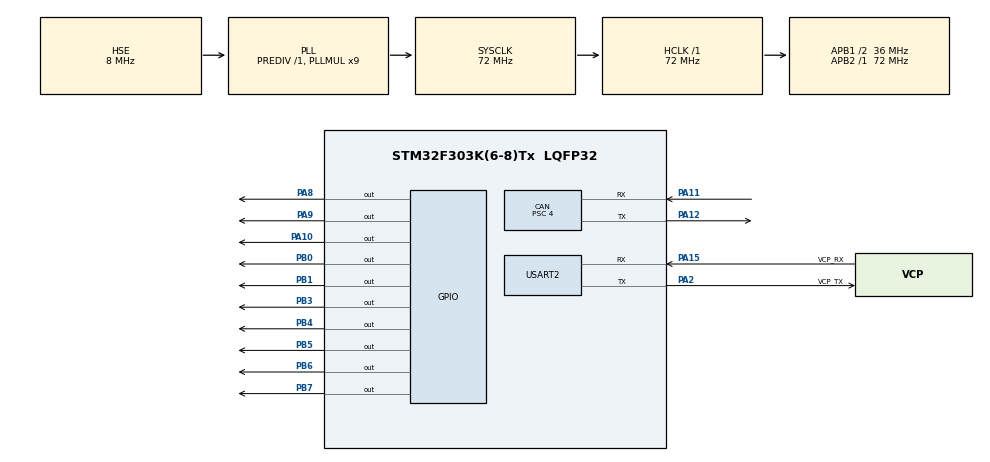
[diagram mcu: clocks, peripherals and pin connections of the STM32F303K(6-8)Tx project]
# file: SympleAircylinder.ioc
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CAN.ABOM=ENABLE
CAN.BS1=CAN_BS1_7TQ
CAN.CalculateTimeQuantum=111.11111111111111
CAN.Prescaler=4
CAN.SJW=CAN_SJW_2TQ
CAN.TXFP=ENABLE
Mcu.Family=STM32F3
Mcu.Name=STM32F303K(6-8)Tx
Mcu.Package=LQFP32
NVIC.CAN_RX0_IRQn=true\:0\:0\:false\:false\:true\:true\:true
NVIC.CAN_RX1_IRQn=true\:0\:0\:false\:false\:true\:true\:true
NVIC.PriorityGroup=NVIC_PRIORITYGROUP_4
PA10.GPIO_PuPd=GPIO_PULLDOWN
PA10.Signal=GPIO_Output
PA11.Mode=Master
PA11.Signal=CAN_RX
PA12.Mode=Master
PA12.Signal=CAN_TX
PA13.GPIO_Label=SWDIO
PA13.Mode=Serial_Wire
PA13.Signal=SYS_JTMS-SWDIO
PA14.GPIO_Label=SWCLK
PA14.Mode=Serial_Wire
PA14.Signal=SYS_JTCK-SWCLK
PA15.GPIO_Label=VCP_RX
PA15.Mode=Asynchronous
PA15.Signal=USART2_RX
PA2.GPIO_Label=VCP_TX
PA2.Mode=Asynchronous
PA2.Signal=USART2_TX
PA8.GPIO_PuPd=GPIO_PULLDOWN
PA8.Signal=GPIO_Output
PA9.GPIO_PuPd=GPIO_PULLDOWN
PA9.Signal=GPIO_Output
PB0.GPIO_PuPd=GPIO_NOPULL
PB0.Signal=GPIO_Output
PB1.GPIO_PuPd=GPIO_NOPULL
PB1.Signal=GPIO_Output
PB3.GPIO_PuPd=GPIO_PULLDOWN
PB3.Signal=GPIO_Output
PB4.GPIO_PuPd=GPIO_PULLDOWN
PB4.Signal=GPIO_Output
PB5.GPIO_PuPd=GPIO_PULLDOWN
PB5.Signal=GPIO_Output
PB6.GPIO_PuPd=GPIO_PULLDOWN
PB6.Signal=GPIO_Output
PB7.GPIO_PuPd=GPIO_PULLDOWN
PB7.Signal=GPIO_Output
PF0\ /\ OSC_IN.Mode=HSE-External-Oscillator
PF0\ /\ OSC_IN.Signal=RCC_OSC_IN
PF1\ /\ OSC_OUT.Mode=HSE-External-Oscillator
PF1\ /\ OSC_OUT.Signal=RCC_OSC_OUT
ProjectManager.HeapSize=0x200
ProjectManager.StackSize=0x400
ProjectManager.TargetToolchain=TrueSTUDIO
RCC.AHBFreq_Value=72000000
RCC.APB1CLKDivider=RCC_HCLK_DIV2
RCC.APB1Freq_Value=36000000
RCC.APB1TimFreq_Value=72000000
RCC.APB2Freq_Value=72000000
RCC.APB2TimFreq_Value=72000000
RCC.CortexFreq_Value=72000000
RCC.HCLKFreq_Value=72000000
RCC.HSE_VALUE=8000000
RCC.HSI_VALUE=8000000
RCC.PLLMUL=RCC_PLL_MUL9
RCC.PLLSourceVirtual=RCC_PLLSOURCE_HSE
RCC.SYSCLKFreq_VALUE=72000000
RCC.SYSCLKSourceVirtual=RCC_SYSCLKSOURCE_PLLCLK
USART2.VirtualMode-Asynchronous=VM_ASYNC
board=NUCLEO-F303K8

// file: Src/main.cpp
/* USER CODE BEGIN Header */
/**
  ******************************************************************************
  * @file           : main.c
  * @brief          : Main program body
  ******************************************************************************
  * @attention
  *
  * <h2><center>&copy; Copyright (c) 2019 STMicroelectronics.
  * All rights reserved.</center></h2>
  *
  * This software component is licensed by ST under BSD 3-Clause license,
  * the "License"; You may not use this file except in compliance with the
  * License. You may obtain a copy of the License at:
  *                        opensource.org/licenses/BSD-3-Clause
  *
  ******************************************************************************
  */
/* USER CODE END Header */

#include "main.h"
#include "can.h"
#include "usart.h"
#include "gpio.h"

/* USER CODE BEGIN Includes */
#include"Application/Application.hpp"
#include "LowlayerHandel.hpp"

/* USER CODE END Includes */

/* USER CODE BEGIN PTD */
extern void FilterConfig();
/* USER CODE END PTD */

/* USER CODE BEGIN PD */
#define RUN
//#define DEBUG
/* USER CODE END PD */

void SystemClock_Config(void);

int main(void)
{

  /* MCU Configuration--------------------------------------------------------*/

  /* Reset of all peripherals, Initializes the Flash interface and the Systick. */
  HAL_Init();

  /* Configure the system clock */
  SystemClock_Config();

  /* Initialize all configured peripherals */
  MX_GPIO_Init();
  MX_CAN_Init();
  MX_USART2_UART_Init();
  /* USER CODE BEGIN 2 */

  LowlayerHandelTypedef hlow;
  FilterConfig();
  App app(&hlow);
//  float a=0;
//  char b;
  /* USER CODE END 2 */

  /* Infinite loop */
  while (1)
  {

    /* USER CODE BEGIN 3 */
#ifdef RUN
	  app.TaskShift();
#endif

#ifdef DEBUG
	  //hlow.DebugLed();
	  hlow.DebugAircylinder(2);

#endif
//	  scanf("%c\r",&b);
//	  printf("a:%f\n\r",a);
	     //scanf("%f\r",&a);

	 //  printf("printok/n/r");

	 // printf("ok\n\r");
//	  hlow.extcan.Send(0x24, 0, 0);
//	  HAL_Delay(1);
  }
  /* USER CODE END 3 */
}

void SystemClock_Config(void)
{
  RCC_OscInitTypeDef RCC_OscInitStruct = {0};
  RCC_ClkInitTypeDef RCC_ClkInitStruct = {0};

  /** Initializes the CPU, AHB and APB busses clocks
  */
  RCC_OscInitStruct.OscillatorType = RCC_OSCILLATORTYPE_HSE;
  RCC_OscInitStruct.HSEState = RCC_HSE_ON;
  RCC_OscInitStruct.HSEPredivValue = RCC_HSE_PREDIV_DIV1;
  RCC_OscInitStruct.HSIState = RCC_HSI_ON;
  RCC_OscInitStruct.PLL.PLLState = RCC_PLL_ON;
  RCC_OscInitStruct.PLL.PLLSource = RCC_PLLSOURCE_HSE;
  RCC_OscInitStruct.PLL.PLLMUL = RCC_PLL_MUL9;
  if (HAL_RCC_OscConfig(&RCC_OscInitStruct) != HAL_OK)
  {
    Error_Handler();
  }
  /** Initializes the CPU, AHB and APB busses clocks
  */
  RCC_ClkInitStruct.ClockType = RCC_CLOCKTYPE_HCLK|RCC_CLOCKTYPE_SYSCLK
                              |RCC_CLOCKTYPE_PCLK1|RCC_CLOCKTYPE_PCLK2;
  RCC_ClkInitStruct.SYSCLKSource = RCC_SYSCLKSOURCE_PLLCLK;
  RCC_ClkInitStruct.AHBCLKDivider = RCC_SYSCLK_DIV1;
  RCC_ClkInitStruct.APB1CLKDivider = RCC_HCLK_DIV2;
  RCC_ClkInitStruct.APB2CLKDivider = RCC_HCLK_DIV1;

  if (HAL_RCC_ClockConfig(&RCC_ClkInitStruct, FLASH_LATENCY_2) != HAL_OK)
  {
    Error_Handler();
  }
}

void Error_Handler(void)
{
}

/************************ (C) COPYRIGHT STMicroelectronics *****END OF FILE****/
